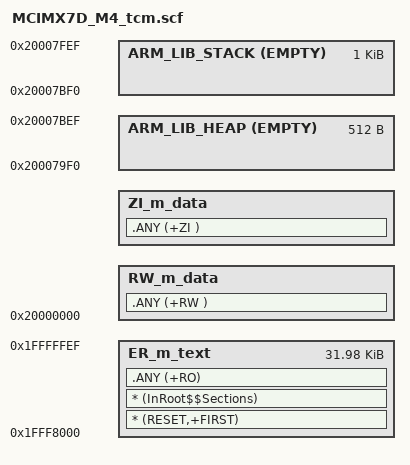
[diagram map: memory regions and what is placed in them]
#! armcc -E --cpu Cortex-M4

; Linker file for Colibri i.MX7S and Colibri i.MX7D
; Storing code and data in the TCML / TCMU sections
;
;              +-------------+
;              |             |  ^
;              |    code     |  |m_text_size
;              |             |  v
; m_text_start +-------------+
;
;
;              +-------------+
;              |             |  ^  ^
;              |    stack    |  |  |STACK_SIZE
;              |             |  |  v
;              +-------------+  |
;              |             |  |  ^
;              |    heap     |  |  |HEAP_SIZE
;              |             |  |  v
;              +-------------+  |
;              +-------------+  |m_data_size
;              |             |  |
;              | normal data |  |
;              |             |  v
; m_data_start +-------------+


#define TCML_code       0x1fff8000
#define TCMU_system     0x20000000
#define OCRAM_code      0x00900000
#define OCRAM_data      0x20200000

#define m_text_start    TCML_code
#define m_text_size     0x7ff0

#define m_data_start    TCMU_system
#define m_data_size     0x7ff0

#define HEAP_SIZE       0x200
#define STACK_SIZE      0x400
#define MY_ALIGN(address, alignment) ((address + (alignment - 1)) AND ~(alignment - 1))


LR_m_text m_text_start m_text_size
{
   ; == Code ==
   ER_m_text m_text_start m_text_size {
    * (RESET,+FIRST)
    * (InRoot$$Sections)
    .ANY (+RO)
  }

  ; == Regular Data ==
  RW_m_data m_data_start  { ; RW data
    .ANY (+RW )
  }
  ZI_m_data +0  { ; ZI data
    .ANY (+ZI )
  }

  ; == Heap ==
  ; The heap is growing from end of regular data towards 
  ; higher addresses
  ARM_LIB_HEAP  (m_data_start + m_data_size - STACK_SIZE - HEAP_SIZE) EMPTY  HEAP_SIZE
  { 
  }
  
  ; == Stack ==
  ; The Stack is growing from end of m_data section down towards
  ; lower addresses.
  ; If the stack overflows, it will grow into the heap section
  ARM_LIB_STACK (m_data_start + m_data_size) EMPTY -STACK_SIZE
  { 
  }

}
